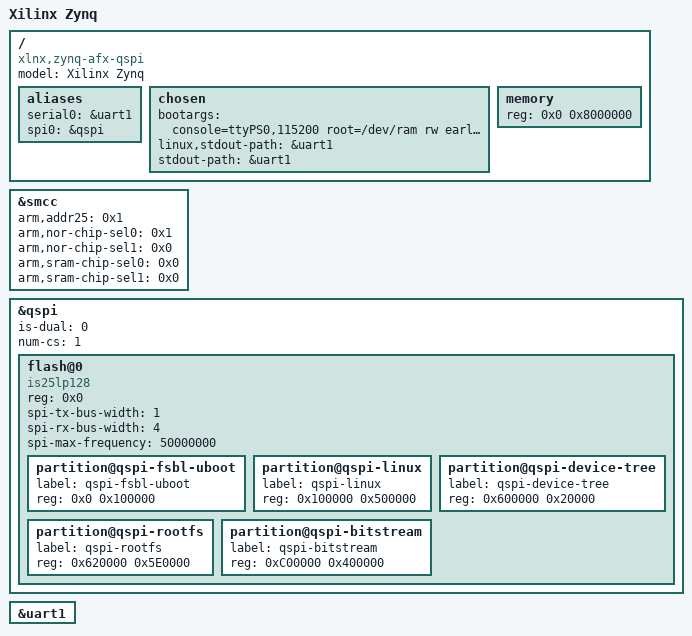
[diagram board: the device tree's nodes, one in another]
/*
 * Device Tree Generator version: 1.1
 *
 * (C) Copyright 2007-2013 Xilinx, Inc.
 * (C) Copyright 2007-2013 Michal Simek
 * (C) Copyright 2007-2012 PetaLogix Qld Pty Ltd
 *
 * Michal SIMEK <monstr@monstr.eu>
 *
 * CAUTION: This file is automatically generated by libgen.
 * Version: Xilinx EDK 14.5 EDK_P.58f
 *
 */
/dts-v1/;
/include/ "zynq-7000.dtsi"

/ {
	compatible = "xlnx,zynq-afx-qspi", "xlnx,zynq-7000";
	model = "Xilinx Zynq";

	aliases {
		serial0 = &uart1;
		spi0 = &qspi;
	};

	chosen {
		bootargs = "console=ttyPS0,115200 root=/dev/ram rw earlyprintk";
		linux,stdout-path = &uart1;
		stdout-path = &uart1;
	};

	memory {
		device_type = "memory";
		reg = <0x0 0x8000000>;
	};
};

&smcc {
	status = "okay";
	arm,addr25 = <0x1>;
	arm,nor-chip-sel0 = <0x1>;
	arm,nor-chip-sel1 = <0x0>;
	arm,sram-chip-sel0 = <0x0>;
	arm,sram-chip-sel1 = <0x0>;
};

&qspi {
	status = "okay";
	is-dual = <0>;
	num-cs = <1>;
	flash@0 {
		compatible = "is25lp128";
		reg = <0x0>;
		spi-tx-bus-width = <1>;
		spi-rx-bus-width = <4>;
		spi-max-frequency = <50000000>;
		#address-cells = <1>;
		#size-cells = <1>;
		partition@qspi-fsbl-uboot {
			label = "qspi-fsbl-uboot";
			reg = <0x0 0x100000>;
		};
		partition@qspi-linux {
			label = "qspi-linux";
			reg = <0x100000 0x500000>;
		};
		partition@qspi-device-tree {
			label = "qspi-device-tree";
			reg = <0x600000 0x20000>;
		};
		partition@qspi-rootfs {
			label = "qspi-rootfs";
			reg = <0x620000 0x5E0000>;
		};
		partition@qspi-bitstream {
			label = "qspi-bitstream";
			reg = <0xC00000 0x400000>;
		};
	};
};

&uart1 {
	status = "okay";
};
